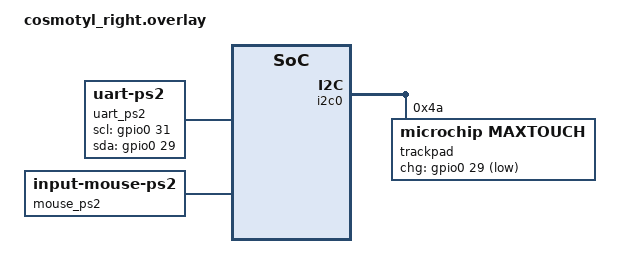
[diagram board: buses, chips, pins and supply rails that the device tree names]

#include "cosmotyl.dtsi"

/ {
    bootloader_key: bootloader_key {
        compatible = "zmk,boot-magic-key";
        key-position = <29>;
        jump-to-bootloader;
    };

    trackpad_listener: trackpad_listener {
        compatible = "zmk,input-listener";
        mode = "trackpad";
        device = <&trackpad>;
    };

    /* ── PS/2 TrackPoint via VIK AD_1/AD_2 ─────────────────────── */
    /* CLK = VIK AD_2 = P0.31                                       */
    /* DATA = VIK AD_1 = P0.29                                      */
    uart_ps2: uart-ps2 {
        compatible = "uart-ps2";
        scl-gpios = <&gpio0 31 GPIO_ACTIVE_HIGH>;
        sda-gpios = <&gpio0 29 GPIO_ACTIVE_HIGH>;
    };

    mouse_ps2: input-mouse-ps2 {
        compatible = "zmk,input-mouse-ps2";
        ps2-device = <&uart_ps2>;
    };

    trackpoint_listener: trackpoint_listener {
        compatible = "zmk,input-listener-ps2";
        device = <&mouse_ps2>;
    };
};

&default_transform {
    col-offset = <7>;
};

/* ── Procyon MaxTouch via VIK I2C ───────────────────────────────── */
&i2c0 {
    status = "okay";

    trackpad: maxtouch@4a {
        compatible = "microchip,maxtouch";
        status = "okay";
        reg = <0x4a>;
        /* CHG on VIK AD_1 = P0.29 */
        chg-gpios = <&gpio0 29 (GPIO_ACTIVE_LOW | GPIO_PULL_UP)>;

        sensor-width = <42>;
        sensor-height = <50>;

        swap-xy;
        /* invert-x; */
        /* invert-y; */
    };
};
